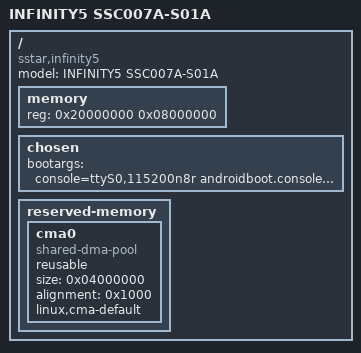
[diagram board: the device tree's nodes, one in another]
/*
* infinity5-BGA128M.dts- Sigmastar
*
* Copyright (c) [2019~2020] SigmaStar Technology.
*
*
* This software is licensed under the terms of the GNU General Public
* License version 2, as published by the Free Software Foundation, and
* may be copied, distributed, and modified under those terms.
*
* This program is distributed in the hope that it will be useful,
* but WITHOUT ANY WARRANTY; without even the implied warranty of
* MERCHANTABILITY or FITNESS FOR A PARTICULAR PURPOSE.  See the
* GNU General Public License version 2 for more details.
*
*/

/dts-v1/;
#include "infinity5.dtsi"

/ {
    model = "INFINITY5 SSC007A-S01A";
    compatible = "sstar,infinity5";

    memory {
        reg = <0x20000000 0x08000000>;
    };

    chosen {
        bootargs = "console=ttyS0,115200n8r androidboot.console=ttyS0 root=/dev/mtdblock2 init=/linuxrc";
    };

/*!!IMPORTANT!! The reserved memory must be 1MB aligned*/
    reserved-memory {
        #address-cells = <1>;
        #size-cells = <1>;
        ranges;

        cma0 {
            compatible = "shared-dma-pool";
            reusable;
            size = <0x04000000>;
            alignment = <0x1000>;
            linux,cma-default;
        };
    };
};
